VERSION ""

NS_ :

BS_:

BU_: SLU TCU ECU ETAS

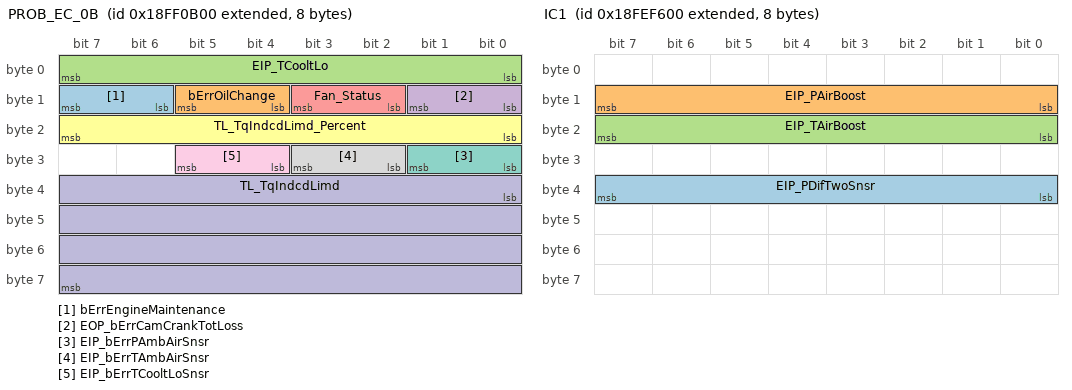
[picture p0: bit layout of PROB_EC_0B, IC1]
BO_ 2566851328 PROB_EC_0B: 8 ECU
 SG_ bErrEngineMaintenance : 14|2@1+ (1,0) [0|1] "" Vector__XXX
 SG_ bErrOilChange : 12|2@1+ (1,0) [0|1] "" Vector__XXX
 SG_ EIP_TCooltLo : 0|8@1+ (1,0) [0|0] "" Vector__XXX
 SG_ EOP_bErrCamCrankTotLoss : 8|2@1+ (1,0) [0|2] "" Vector__XXX
 SG_ Fan_Status : 10|2@1+ (1,0) [0|3] "" Vector__XXX
 SG_ TL_TqIndcdLimd_Percent : 16|8@1+ (1,0) [0|0] "" Vector__XXX
 SG_ EIP_bErrPAmbAirSnsr : 24|2@1+ (1,0) [0|0] "" Vector__XXX
 SG_ EIP_bErrTAmbAirSnsr : 26|2@1+ (1,0) [0|0] "" Vector__XXX
 SG_ EIP_bErrTCooltLoSnsr : 28|2@1+ (1,0) [0|0] "" Vector__XXX
 SG_ TL_TqIndcdLimd : 32|32@1+ (1,0) [0|0] "" Vector__XXX

BO_ 2566842624 LFC: 8 ECU
 SG_ EOP_FuCns : 0|32@1- (0.5,0) [0|2105540607.5] "L" Vector__XXX

BO_ 2566850816 PROB_EC_09: 8 ECU
 SG_ EIP_bErrAccrSnsr1 : 34|2@1+ (1,0) [0|3] ""  TCU
 SG_ EIP_bErrAutStrtSwt : 32|2@1+ (1,0) [0|3] ""  TCU
 SG_ EIP_bErrCmbtSwt : 30|2@1+ (1,0) [0|3] ""  TCU
 SG_ EIP_bErrStpSwt : 28|2@1+ (1,0) [0|3] ""  TCU
 SG_ EIP_StAirFilClgg : 26|2@1+ (1,0) [0|3] ""  TCU
 SG_ WM_bAcvLimp : 24|2@1+ (1,0) [0|3] ""  TCU
 SG_ EIP_bAcvEmgcyShtdwnForOvspd : 22|2@1+ (1,0) [0|3] ""  TCU
 SG_ EIP_bAcvFuCutoffForOvspd : 20|2@1+ (1,0) [0|3] ""  TCU
 SG_ EOP_bAcvCdstFan : 18|2@1+ (1,0) [0|3] ""  TCU
 SG_ EOP_bReqCoolgFanMax : 16|2@1+ (1,0) [0|3] ""  TCU
 SG_ SC_bAcvDDStrtrNotTurn : 14|2@1+ (1,0) [0|3] ""  TCU
 SG_ SC_bAcvDDPinionNotEngd : 12|2@1+ (1,0) [0|3] ""  TCU
 SG_ EIP_bErrGridHeatr : 10|2@1+ (1,0) [0|3] ""  TCU
 SG_ WM_bAcvTCooltHiOvWarn : 8|2@1+ (1,0) [0|3] ""  TCU
 SG_ WM_bAcvLvlOilWarn : 6|2@1+ (1,0) [0|3] ""  TCU
 SG_ WM_bAcvEmgcyShtdwn : 0|2@1+ (1,0) [0|3] ""  TCU
 SG_ WM_bAcvRedn : 4|2@1+ (1,0) [0|3] "" Vector__XXX
 SG_ WM_bAcvWarn : 2|2@1+ (1,0) [0|3] "" Vector__XXX
 SG_ EIP_bErrAccrSnsr2 : 36|2@1+ (1,0) [0|3] "" Vector__XXX
 SG_ EIP_bErrUClmp30Snsr : 38|2@1+ (1,0) [0|3] "" Vector__XXX
 SG_ EIP_bErrAcvUClmp30Snsr : 40|2@1+ (1,0) [0|3] "" Vector__XXX
 SG_ INP_bErrCamsftSnsr : 54|2@1+ (1,0) [0|3] "" Vector__XXX
 SG_ EIP_bErrAcvUClmp48Snsr : 42|2@1+ (1,0) [0|3] "" Vector__XXX
 SG_ EIP_bErrAcvUClmp50 : 44|2@1+ (1,0) [0|3] "" Vector__XXX
 SG_ EIP_bErrAccrRedncy : 46|2@1+ (1,0) [0|3] "" Vector__XXX
 SG_ EOP_bErrAccrTotLoss : 48|2@1+ (1,0) [0|3] "" Vector__XXX
 SG_ WM_bAcvTEcuWarn : 50|2@1+ (1,0) [0|3] "" Vector__XXX
 SG_ INP_bErrCrnksftSnsr : 52|2@1+ (1,0) [0|3] "" Vector__XXX
 SG_ EIP_bErrPFuSnsr : 56|2@1+ (1,0) [0|3] "" Vector__XXX
 SG_ WM_bPRailTooLoMsg : 58|2@1+ (1,0) [0|3] "" Vector__XXX
 SG_ WM_bPRailHiMsg : 60|2@1+ (1,0) [0|3] "" Vector__XXX
 SG_ WM_bPRailTooHiMsg : 62|2@1+ (1,0) [0|3] "" Vector__XXX

BO_ 2566851326 PROB_EC_0A: 8 ECU
 SG_ EIP_bErrLvlOilSnsr : 36|2@1+ (1,0) [0|3] "" Vector__XXX
 SG_ WM_bAcvPOilWarn : 32|2@1+ (1,0) [0|3] "" Vector__XXX
 SG_ EIP_bErrTOilSnsr : 34|2@1+ (1,0) [0|3] "" Vector__XXX
 SG_ EIP_bErrPOilSnsr : 30|2@1+ (1,0) [0|3] ""  TCU
 SG_ WM_bAcvLvlCooltWarn : 28|2@1+ (1,0) [0|3] ""  TCU
 SG_ EIP_bErrLvlCooltSnsr : 26|2@1+ (1,0) [0|3] ""  TCU
 SG_ EIP_bErrTCooltHiSnsr : 24|2@1+ (1,0) [0|3] ""  TCU
 SG_ EIP_bErrInjr8 : 14|2@1+ (1,0) [0|3] ""  TCU
 SG_ EIP_bErrInjr7 : 12|2@1+ (1,0) [0|3] ""  TCU
 SG_ EIP_bErrInjr6 : 10|2@1+ (1,0) [0|3] ""  TCU
 SG_ EIP_bErrInjr5 : 8|2@1+ (1,0) [0|3] ""  TCU
 SG_ EIP_bErrInjr4 : 6|2@1+ (1,0) [0|3] ""  TCU
 SG_ EIP_bErrInjr3 : 4|2@1+ (1,0) [0|3] ""  TCU
 SG_ EIP_bErrInjr2 : 2|2@1+ (1,0) [0|3] ""  TCU
 SG_ EIP_bErrInjr1 : 0|2@1+ (1,0) [0|3] ""  TCU
 SG_ EIP_bAcvSbmgSwt : 38|2@1+ (1,0) [0|3] "" Vector__XXX
 SG_ EOP_bAcvStrtr : 46|2@1+ (1,0) [0|3] "" Vector__XXX
 SG_ EIP_bAcvImdtStrtSwt : 42|2@1+ (1,0) [0|3] "" Vector__XXX
 SG_ EIP_bAcvCmbtSwt : 44|2@1+ (1,0) [0|3] "" Vector__XXX
 SG_ EIP_bAcvCmndrHtchSwt : 40|2@1+ (1,0) [0|3] "" Vector__XXX
 SG_ InjBankAOverCrrnt : 48|2@1+ (2,0) [0|2] "" Vector__XXX
 SG_ InjBankBOverCrrnt : 50|2@1+ (2,0) [0|2] "" Vector__XXX
 SG_ InjBankCOverCrrnt : 52|2@1+ (2,0) [0|2] "" Vector__XXX
 SG_ InjBankDOverCrrnt : 54|2@1+ (2,0) [0|2] "" Vector__XXX
 SG_ GridHeaterReady : 56|2@1+ (1,0) [0|0] "" Vector__XXX

BO_ 2566847488 DD: 8 ECU
 SG_ EIP_LvlFu : 8|8@1+ (0.4,0) [0|100] "%"  TCU

BO_ 2566846208 VEP1: 8 ECU
 SG_ EIP_UClmp30 : 48|16@1+ (0.05,0) [0|3212.75] "V"  TCU

BO_ 2566845952 IC1: 8 ECU
 SG_ EIP_PDifTwoSnsr : 32|8@1+ (0.05,0) [0|12.5] "kPa" Vector__XXX
 SG_ EIP_PAirBoost : 8|8@1+ (2,0) [0|500] "kPa" Vector__XXX
 SG_ EIP_TAirBoost : 16|8@1+ (1,-40) [-40|210] "degC"  TCU

BO_ 2566845696 AMB: 8 ECU
 SG_ EIP_TAmbAir : 24|16@1+ (0.03125,-273) [-273|1735] "deg C"  TCU
 SG_ EIP_PAmbAir : 0|8@1+ (0.5,0) [0|125] "kPa"  TCU

BO_ 2566844928 LFE: 8 ECU
 SG_ IC_InstFuCnsMm3PerHour : 0|16@1+ (0.05,0) [0|3212.75] "L/h"  TCU

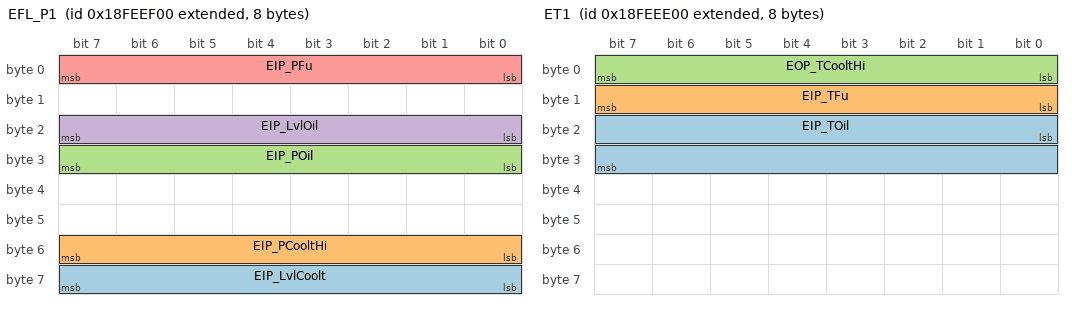
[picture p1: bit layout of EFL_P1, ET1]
BO_ 2566844160 EFL_P1: 8 ECU
 SG_ EIP_LvlCoolt : 56|8@1+ (0.4,0) [0|100] "%"  TCU
 SG_ EIP_PCooltHi : 48|8@1+ (2,0) [0|500] "kPa"  TCU
 SG_ EIP_POil : 24|8@1+ (4,0) [0|1000] "kPa"  TCU
 SG_ EIP_LvlOil : 16|8@1+ (0.4,0) [0|100] "%"  TCU
 SG_ EIP_PFu : 0|8@1+ (4,0) [0|1000] "kPa"  TCU

BO_ 2566843904 ET1: 8 ECU
 SG_ EIP_TOil : 16|16@1+ (0.03125,-273) [-273|1735] "degC"  TCU
 SG_ EIP_TFu : 8|8@1+ (1,-40) [-40|210] "degC"  TCU
 SG_ EOP_TCooltHi : 0|8@1+ (1,-40) [-40|210] "degC"  TCU

BO_ 2566839040 EFL_P2: 8 ECU
 SG_ RPG_PercgFmuVlv2Req : 48|16@1+ (0.00390625,0) [0|251] "Mpa" Vector__XXX
 SG_ EIP_PRail : 16|16@1+ (0.00390625,0) [0|251] "MPa" Vector__XXX

BO_ 2566784768 ET: 8 ECU
 SG_ EIP_TExhLe : 16|16@1+ (0.03125,-273) [-273|1735] "degC"  TCU
 SG_ EIP_TExhRi : 0|16@1+ (0.03125,-273) [-273|1735] "degC"  TCU

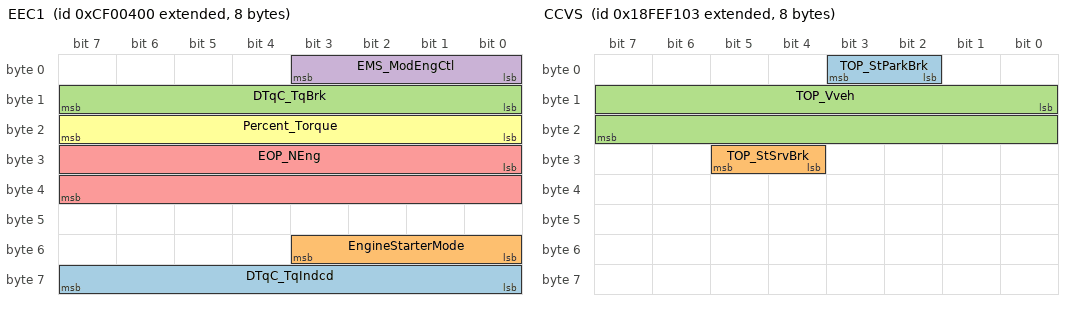
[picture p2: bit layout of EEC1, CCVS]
BO_ 2364539904 EEC1: 8 ECU
 SG_ DTqC_TqIndcd : 56|8@1+ (1,-125) [-125|125] "%" Vector__XXX
 SG_ EngineStarterMode : 48|4@1+ (1,0) [0|15] "" Vector__XXX
 SG_ DTqC_TqBrk : 8|8@1+ (1,-125) [-125|125] "%" Vector__XXX
 SG_ EMS_ModEngCtl : 0|4@1+ (1,0) [0|15] "" Vector__XXX
 SG_ EOP_NEng : 24|16@1+ (0.125,0) [0|8031.875] "rpm"  TCU
 SG_ Percent_Torque : 16|8@1+ (1,-125) [-125|125] "%"  TCU

BO_ 2364539648 EEC2: 3 ECU
 SG_ EIP_PercgAccr2 : 32|8@1+ (0.4,0) [0|100] "%" Vector__XXX
 SG_ DTqC_TqFric : 16|8@1+ (1,0) [0|250] "%" Vector__XXX
 SG_ EIP_PercgAccr1 : 8|8@1+ (0.4,0) [0|100] "%"  TCU

BO_ 2365428224 EOI: 8 ECU
 SG_ EngineOperatingState : 0|4@1+ (1,0) [0|15] "" Vector__XXX

BO_ 2566873347 PROB_TC_061: 8 TCU
 SG_ TOP_NEngReq : 0|32@1+ (1,0) [0|0] "" Vector__XXX

BO_ 2565872899 SAS: 8 TCU
 SG_ TIP_PercgSteer : 0|16@1+ (0.0009765625,-31.374) [-31.374|31.374] "rad" Vector__XXX

BO_ 2566844675 CCVS: 8 TCU
 SG_ TOP_StParkBrk : 2|2@1+ (1,0) [0|3] "" Vector__XXX
 SG_ TOP_StSrvBrk : 28|2@1+ (1,0) [0|3] "" Vector__XXX
 SG_ TOP_Vveh : 8|16@1+ (0.00390625,0) [0|250.996] "km/h" Vector__XXX

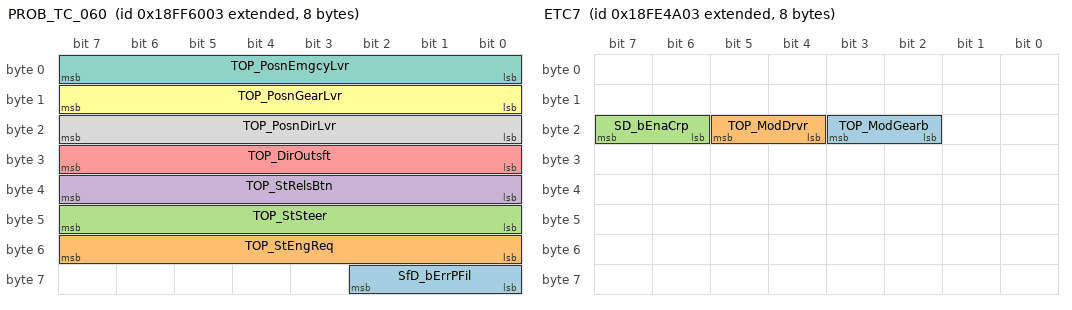
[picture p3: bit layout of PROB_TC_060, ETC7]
BO_ 2566873091 PROB_TC_060: 8 TCU
 SG_ SfD_bErrPFil : 56|3@1+ (1,0) [0|7] "" Vector__XXX
 SG_ TOP_StEngReq : 48|8@1+ (1,0) [0|255] "" Vector__XXX
 SG_ TOP_StSteer : 40|8@1+ (1,0) [0|255] "" Vector__XXX
 SG_ TOP_StRelsBtn : 32|8@1+ (1,0) [0|255] "" Vector__XXX
 SG_ TOP_DirOutsft : 24|8@1+ (1,0) [0|255] "" Vector__XXX
 SG_ TOP_PosnGearLvr : 8|8@1+ (1,0) [0|255] "" Vector__XXX
 SG_ TOP_PosnEmgcyLvr : 0|8@1+ (1,0) [0|255] "" Vector__XXX
 SG_ TOP_PosnDirLvr : 16|8@1+ (1,0) [0|0] "" Vector__XXX

BO_ 2348875779 TC1: 8 TCU
 SG_ SD_bStallLaunAcv : 50|4@1+ (1,0) [0|15] "" Vector__XXX

BO_ 2566801923 ETC7: 8 TCU
 SG_ TOP_ModGearb : 18|2@1+ (1,0) [0|3] "" Vector__XXX
 SG_ TOP_ModDrvr : 20|2@1+ (1,0) [0|3] "" Vector__XXX
 SG_ SD_bEnaCrp : 22|2@1+ (1,0) [0|3] "" Vector__XXX

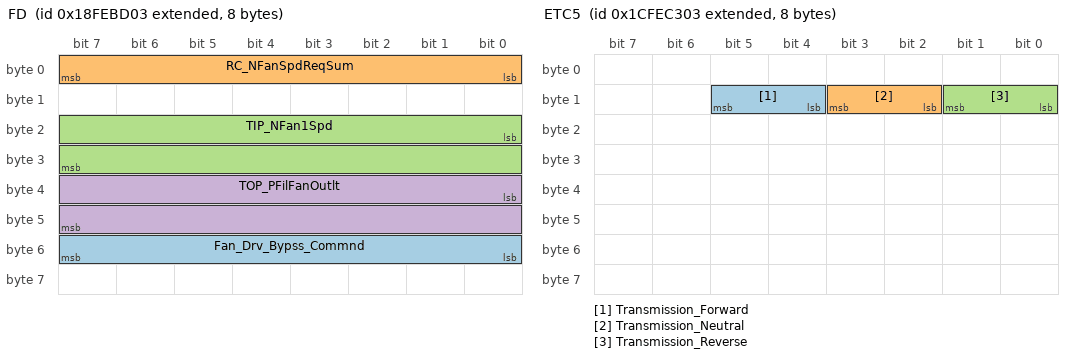
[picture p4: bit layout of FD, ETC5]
BO_ 2566831363 FD: 8 TCU
 SG_ Fan_Drv_Bypss_Commnd : 48|8@1+ (0.4,0) [0|100] "%" Vector__XXX
 SG_ RC_NFanSpdReqSum : 0|8@1+ (0.4,0) [0|100] "%" Vector__XXX
 SG_ TIP_NFan1Spd : 16|16@1+ (0.125,0) [0|8031.875] "rpm" Vector__XXX
 SG_ TOP_PFilFanOutlt : 32|16@1+ (0.5,0) [0|32127.5] "kPa" Vector__XXX

BO_ 2365449731 HBS: 8 TCU
 SG_ SfD_bErrPAcmtrSrvBrkLo : 26|2@1+ (1,0) [0|3] "" Vector__XXX

BO_ 2633941763 ETC5: 8 TCU
 SG_ Transmission_Forward : 12|2@1+ (1,0) [0|3] "" Vector__XXX
 SG_ Transmission_Neutral : 10|2@1+ (1,0) [0|3] "" Vector__XXX
 SG_ Transmission_Reverse : 8|2@1+ (1,0) [0|3] "" Vector__XXX

BO_ 2566846467 TRF1: 8 TCU
 SG_ TIP_TTqcInlt : 32|16@1+ (0.03125,-273) [-273|1735] "deg C" Vector__XXX

BO_ 2565866755 ETC2: 8 TCU
 SG_ GS_IdxGearDes : 0|8@1+ (1,-125) [-125|125] "" Vector__XXX
 SG_ TOP_Trans_ActlGearRtio : 8|16@1+ (0.001,0) [0|64.255] "" Vector__XXX
 SG_ TOP_IdxGearAcv : 24|8@1+ (1,-125) [-125|125] "" Vector__XXX
 SG_ Trans_Reqstd_Rng : 40|16@1+ (1,0) [0|255] "" Vector__XXX
 SG_ Trans_Current_Rng : 48|16@1+ (1,0) [0|255] "" Vector__XXX

BO_ 2364539395 ETC1: 8 TCU
 SG_ TIP_NOutsft : 8|16@1+ (0.125,0) [0|8031.875] "rpm" Vector__XXX

BO_ 2566873603 PROB_TC_062: 8 TCU
 SG_ TIP_PSrvBrk : 0|2@1+ (1,0) [0|0] "" Vector__XXX
 SG_ TIP_bErrFanSoln : 22|2@1+ (1,0) [0|0] "" Vector__XXX
 SG_ SfD_bErrPTqcInltLo : 30|2@1+ (1,0) [0|0] "" Vector__XXX
 SG_ TOP_bErrTqcOutltP : 32|2@1+ (1,0) [0|0] "" Vector__XXX
 SG_ TOP_bErrTqcInltT : 34|2@1+ (1,0) [0|0] "" Vector__XXX
 SG_ TOP_bErrTqcOutltT : 36|2@1+ (1,0) [0|0] "" Vector__XXX
 SG_ SD_bEnaDirLock : 38|2@1+ (1,0) [0|0] "" Vector__XXX
 SG_ TOP_Brake_Pstn_Oil_Prssure : 40|2@1+ (1,0) [0|0] "" Vector__XXX
 SG_ EIP_bAcvEmgcyShtdwn : 42|2@1+ (1,0) [0|0] "" Vector__XXX
 SG_ SfD_bErrSrvBrkRiWear : 2|2@1+ (1,0) [0|0] "" Vector__XXX
 SG_ SfD_bErrSrvBrkLeWear : 4|2@1+ (1,0) [0|0] "" Vector__XXX
 SG_ TIP_StParkBrk : 6|2@1+ (1,0) [0|0] "" Vector__XXX
 SG_ TIP_bErrFanOilT : 8|2@1+ (1,0) [0|0] "" Vector__XXX
 SG_ TIP_bErrFanOilP : 10|2@1+ (1,0) [0|0] "" Vector__XXX
 SG_ TIP_bErrFanOilLimSwtLvl : 12|2@1+ (1,0) [0|0] "" Vector__XXX
 SG_ SfD_bErrPFilFanClgg : 14|2@1+ (1,0) [0|0] "" Vector__XXX
 SG_ SfD_bErrTOilHi : 16|2@1+ (1,0) [0|0] "" Vector__XXX
 SG_ SfD_bErrSrvBrkRiLeWear : 18|2@1+ (1,0) [0|0] "" Vector__XXX
 SG_ SfD_bErrTOilLo : 20|2@1+ (1,0) [0|0] "" Vector__XXX
 SG_ SfD_bErrPHydSteerUniLo : 24|2@1+ (1,0) [0|0] "" Vector__XXX
 SG_ SfD_bErrPFilAnclryOutltLo : 26|2@1+ (1,0) [0|0] "" Vector__XXX
 SG_ SfD_bErrPLubOutltLo : 28|2@1+ (1,0) [0|0] "" Vector__XXX
 SG_ TOP_bErrTrvlDir : 46|2@1+ (1,0) [0|0] "" Vector__XXX
 SG_ TIP_bErrOutsftN : 44|2@1+ (1,0) [0|0] "" Vector__XXX
 SG_ TOP_bErrTqcInltP : 50|2@1+ (1,0) [0|0] "" Vector__XXX
 SG_ TOP_bErrSrvBrkAcmtrP : 48|2@1+ (1,0) [0|0] "" Vector__XXX
 SG_ SD_LvlHill : 56|8@1+ (1,-125) [-125|125] "" Vector__XXX

BO_ 2566877193 PROB_ETAS_1: 8 ETAS
 SG_ ETAS_RS_PerSec : 0|32@1+ (1,0) [0|10000] "" Vector__XXX

BO_ 2566877449 PROB_ETAS_2: 8 ETAS
 SG_ ETAS_Torque : 0|32@1+ (1,0) [0|10000] "" Vector__XXX

CM_ BU_ SLU "Shift Lever Unit";
CM_ BU_ TCU "Transmission Control Unit";
CM_ BU_ ECU "Engine Control Unit";
CM_ BU_ ETAS "ETAS";
CM_ BO_ 2566851328 "PROB_EC_0B Engine Control";
CM_ SG_ 2566851328 bErrEngineMaintenance "Alternator";
CM_ SG_ 2566851328 bErrOilChange "Alternator";
CM_ SG_ 2566851328 Fan_Status "Fan Status";
CM_ SG_ 2566851328 TL_TqIndcdLimd_Percent "%";
CM_ BO_ 2566842624 " Fuel Consumption (Liquid) - LFC";
CM_ SG_ 2566842624 EOP_FuCns "Engine Trip Fuel";
CM_ BO_ 2566850816 "PROB_EC_09 Engine Control";
CM_ BO_ 2566851326 "PROB_EC_0A Engine Control";
CM_ SG_ 2566851326 EIP_bErrTOilSnsr "
";
CM_ SG_ 2566851326 GridHeaterReady "PHC_bAcvPreAcvnGridHeatr=0 oldu?unda motor ön ?s?tma sistemi bak?m?ndan çal??t?r?lmaya haz?rd?r.";
CM_ BO_ 2566847488 "Dash Display";
CM_ SG_ 2566847488 EIP_LvlFu "Fuel Level 1";
CM_ BO_ 2566846208 "Vehicle Electrical Power 1";
CM_ SG_ 2566846208 EIP_UClmp30 "Keyswitch Battery Potential";
CM_ BO_ 2566845952 "Inlet/Exaust Conditions 1";
CM_ SG_ 2566845952 EIP_PDifTwoSnsr "Engine Air Filter 1 Differential Pressure";
CM_ SG_ 2566845952 EIP_PAirBoost "Engine Intake Manifold #1 Pressure";
CM_ SG_ 2566845952 EIP_TAirBoost "Engine Intake Manifold 1 Temperature";
CM_ BO_ 2566845696 "Ambient Conditions";
CM_ SG_ 2566845696 EIP_TAmbAir "Ambient Air Temperature";
CM_ SG_ 2566845696 EIP_PAmbAir "Ambient Air Pressure";
CM_ BO_ 2566844928 "Fuel Economy (Liquid)";
CM_ SG_ 2566844928 IC_InstFuCnsMm3PerHour "Engine Fuel Rate";
CM_ BO_ 2566844160 "Engine Fluid Level Pressure 1";
CM_ SG_ 2566844160 EIP_LvlCoolt "Engine Coolant Level";
CM_ SG_ 2566844160 EIP_PCooltHi "Engine Coolant Pressure";
CM_ SG_ 2566844160 EIP_POil "Engine Oil Pressure";
CM_ SG_ 2566844160 EIP_LvlOil "Engine Oil Level";
CM_ SG_ 2566844160 EIP_PFu "Engine Fuel Delivery Pressure";
CM_ BO_ 2566843904 "Engine Temperature 1";
CM_ SG_ 2566843904 EIP_TOil "Engine Oil Temperature 1";
CM_ SG_ 2566843904 EIP_TFu "Engine Fuel Temperature 1";
CM_ SG_ 2566843904 EOP_TCooltHi "Engine Coolant Temperature";
CM_ BO_ 2566839040 "Engine Fluid Level Pressure 2";
CM_ SG_ 2566839040 RPG_PercgFmuVlv2Req "Engine Injector Metering Rail 2 Pressure";
CM_ SG_ 2566839040 EIP_PRail "Engine Injection Control Pressure";
CM_ BO_ 2566784768 "Exhaust Temperature";
CM_ SG_ 2566784768 EIP_TExhLe "Engine Exhaust Gas Temperature - Left Manifold";
CM_ SG_ 2566784768 EIP_TExhRi "Engine Exhaust Gas Temperature - Right Manifold";
CM_ BO_ 2364539904 "Electronic Engine Controller 1";
CM_ SG_ 2364539904 DTqC_TqIndcd "Engine Demand – Percent Torque";
CM_ SG_ 2364539904 EngineStarterMode "Engine Starter Mode";
CM_ SG_ 2364539904 DTqC_TqBrk "Driver's Demand Engine - Percent Torque";
CM_ SG_ 2364539904 EMS_ModEngCtl "Engine Torque Mode";
CM_ SG_ 2364539904 EOP_NEng "Engine Speed";
CM_ SG_ 2364539904 Percent_Torque "Actual Engine - Percent Torque";
CM_ BO_ 2364539648 "Electronic Engine Controller 2";
CM_ SG_ 2364539648 EIP_PercgAccr2 "Accelerator Pedal Position 2";
CM_ SG_ 2364539648 DTqC_TqFric "Engine Percent Load At Current Speed";
CM_ SG_ 2364539648 EIP_PercgAccr1 "Accelerator Pedal Position 1";
CM_ BO_ 2365428224 "Engine Operating Information";
CM_ SG_ 2365428224 EngineOperatingState "Engine Operating State";
CM_ BO_ 2566873347 "PROB_TC_061 Transmission Control";
CM_ BO_ 2565872899 "Steering Angle Sensor Information";
CM_ SG_ 2565872899 TIP_PercgSteer "Steering Wheel Angle";
CM_ BO_ 2566844675 "Cruise Control/Vehicle Speeds";
CM_ SG_ 2566844675 TOP_StParkBrk "Parking Brake Switch";
CM_ SG_ 2566844675 TOP_StSrvBrk "Brake Switch";
CM_ SG_ 2566844675 TOP_Vveh "Wheel-Based Vehicle Speed";
CM_ BO_ 2566873091 "PROB_TC_060 Transmission Control";
CM_ BO_ 2348875779 "Transmission Control 1";
CM_ SG_ 2348875779 SD_bStallLaunAcv "Transmission Requested Launch Gear";
CM_ BO_ 2566801923 "Electronic Transmission Controller 7";
CM_ SG_ 2566801923 TOP_ModGearb "Transmission Mode 3 Indicator";
CM_ SG_ 2566801923 TOP_ModDrvr "Transmission Mode 2 Indicator";
CM_ SG_ 2566801923 SD_bEnaCrp "Transmission Mode 1 Indicator";
CM_ BO_ 2566831363 "Fan Drive";
CM_ SG_ 2566831363 Fan_Drv_Bypss_Commnd "Fan Drive Bypass Command Status";
CM_ SG_ 2566831363 RC_NFanSpdReqSum "Estimated Percent Fan Speed";
CM_ SG_ 2566831363 TIP_NFan1Spd "Fan Speed";
CM_ SG_ 2566831363 TOP_PFilFanOutlt "Hydraulic Fan Motor Pressure";
CM_ BO_ 2365449731 "Hydraulic Braking System";
CM_ SG_ 2365449731 SfD_bErrPAcmtrSrvBrkLo "Hydraulic Brake Fluid Level Switch";
CM_ BO_ 2633941763 "Electronic Transmission Controller 5";
CM_ SG_ 2633941763 Transmission_Forward "Transmission Forward Direction Switch";
CM_ SG_ 2633941763 Transmission_Neutral "Transmission Neutral Switch";
CM_ SG_ 2633941763 Transmission_Reverse "Transmission Reverse Direction Switch";
CM_ BO_ 2566846467 "Transmission Fluids 1";
CM_ SG_ 2566846467 TIP_TTqcInlt "Transmission Oil Temperature";
CM_ BO_ 2565866755 "Electronic Transmission Controller 2";
CM_ SG_ 2565866755 GS_IdxGearDes "Transmission Selected Gear";
CM_ SG_ 2565866755 TOP_Trans_ActlGearRtio "Transmission Actual Gear Ratio";
CM_ SG_ 2565866755 TOP_IdxGearAcv "Transmission Current Gear";
CM_ SG_ 2565866755 Trans_Reqstd_Rng "Transmission Requested Range";
CM_ SG_ 2565866755 Trans_Current_Rng "Transmission Current Range";
CM_ BO_ 2364539395 "Electronic Transmission Controller 1";
CM_ SG_ 2364539395 TIP_NOutsft "Transmission Output Shaft Speed";
CM_ BO_ 2566873603 "PROB_TC_062 Transmission Control";
CM_ BO_ 2566877193 "ETAS1";
CM_ BO_ 2566877449 "ETAS2";
BA_DEF_ SG_  "SigType" ENUM  "Default","Range","RangeSigned","ASCII","Discrete","Control","ReferencePGN","DTC","StringDelimiter","StringLength","StringLengthControl","MessageCounter","MessageChecksum";
BA_DEF_ SG_  "GenSigEVName" STRING ;
BA_DEF_ SG_  "GenSigILSupport" ENUM  "No","Yes";
BA_DEF_ SG_  "GenSigSendType" ENUM  "Cyclic","OnWrite","OnWriteWithRepetition","OnChange","OnChangeWithRepetition","IfActive","IfActiveWithRepetition","NoSigSendType";
BA_DEF_ SG_  "GenSigStartValue" INT 0 2147483647;
BA_DEF_ BO_  "GenMsgILSupport" ENUM  "No","Yes";
BA_DEF_ BU_  "NmStationAddress" INT 0 255;
BA_DEF_ BO_  "GenMsgSendType" ENUM  "cyclic","NotUsed","IfActive","NotUsed","NotUsed","NotUsed","NotUsed","NotUsed","noMsgSendType";
BA_DEF_ BO_  "GenMsgRequestable" INT 0 1;
BA_DEF_ BO_  "GenMsgCycleTime" INT 0 3600000;
BA_DEF_  "DBName" STRING ;
BA_DEF_  "BusType" STRING ;
BA_DEF_  "ProtocolType" STRING ;
BA_DEF_ BO_  "VFrameFormat" ENUM  "StandardCAN","ExtendedCAN","reserved","J1939PG";
BA_DEF_DEF_  "SigType" "Default";
BA_DEF_DEF_  "GenSigEVName" "Env@Nodename_@Signame";
BA_DEF_DEF_  "GenSigILSupport" "Yes";
BA_DEF_DEF_  "GenSigSendType" "NoSigSendType";
BA_DEF_DEF_  "GenSigStartValue" 0;
BA_DEF_DEF_  "GenMsgILSupport" "Yes";
BA_DEF_DEF_  "NmStationAddress" 254;
BA_DEF_DEF_  "GenMsgSendType" "noMsgSendType";
BA_DEF_DEF_  "GenMsgRequestable" 1;
BA_DEF_DEF_  "GenMsgCycleTime" 0;
BA_DEF_DEF_  "DBName" "";
BA_DEF_DEF_  "BusType" "CAN";
BA_DEF_DEF_  "ProtocolType" "J1939";
BA_DEF_DEF_  "VFrameFormat" "J1939PG";
BA_ "DBName" "canidentifiers";
BA_ "GenMsgCycleTime" BO_ 2566851328 10000;
BA_ "GenMsgSendType" BO_ 2566850816 0;
BA_ "GenMsgCycleTime" BO_ 2566850816 50;
BA_ "GenMsgSendType" BO_ 2566851326 0;
BA_ "GenMsgCycleTime" BO_ 2566851326 50;
BA_ "GenMsgSendType" BO_ 2566847488 0;
BA_ "GenMsgCycleTime" BO_ 2566847488 1000;
BA_ "GenMsgSendType" BO_ 2566846208 0;
BA_ "GenMsgCycleTime" BO_ 2566846208 1000;
BA_ "GenMsgSendType" BO_ 2566845952 0;
BA_ "GenMsgCycleTime" BO_ 2566845952 500;
BA_ "GenSigStartValue" SG_ 2566845952 EIP_TAirBoost 40;
BA_ "GenMsgSendType" BO_ 2566845696 0;
BA_ "GenMsgCycleTime" BO_ 2566845696 1000;
BA_ "GenSigStartValue" SG_ 2566845696 EIP_TAmbAir 8736;
BA_ "GenMsgSendType" BO_ 2566844928 0;
BA_ "GenMsgCycleTime" BO_ 2566844928 100;
BA_ "GenMsgSendType" BO_ 2566844160 0;
BA_ "GenMsgCycleTime" BO_ 2566844160 1000;
BA_ "GenMsgSendType" BO_ 2566843904 0;
BA_ "GenMsgCycleTime" BO_ 2566843904 1000;
BA_ "GenSigStartValue" SG_ 2566843904 EIP_TOil 8736;
BA_ "GenSigStartValue" SG_ 2566843904 EIP_TFu 40;
BA_ "GenSigStartValue" SG_ 2566843904 EOP_TCooltHi 40;
BA_ "GenMsgCycleTime" BO_ 2566839040 500;
BA_ "GenMsgSendType" BO_ 2566839040 0;
BA_ "GenMsgCycleTime" BO_ 2566784768 500;
BA_ "GenMsgSendType" BO_ 2566784768 0;
BA_ "GenSigStartValue" SG_ 2566784768 EIP_TExhLe 8736;
BA_ "GenSigStartValue" SG_ 2566784768 EIP_TExhRi 8736;
BA_ "GenMsgCycleTime" BO_ 2364539904 10;
BA_ "GenMsgSendType" BO_ 2364539904 0;
BA_ "GenSigStartValue" SG_ 2364539904 DTqC_TqIndcd 125;
BA_ "GenSigStartValue" SG_ 2364539904 DTqC_TqBrk 125;
BA_ "GenSigStartValue" SG_ 2364539904 Percent_Torque 125;
BA_ "GenMsgCycleTime" BO_ 2364539648 50;
BA_ "GenMsgSendType" BO_ 2364539648 0;
BA_ "NmStationAddress" BU_ SLU 5;
BA_ "NmStationAddress" BU_ TCU 3;
BA_ "NmStationAddress" BU_ ECU 0;
BA_ "NmStationAddress" BU_ ETAS 9;
VAL_ 2566851328 bErrEngineMaintenance 1 "Error" 0 "No Error" ;
VAL_ 2566851328 bErrOilChange 1 "Error" 0 "No Error" ;
VAL_ 2566851328 EOP_bErrCamCrankTotLoss 0 "NO ERROR" 1 "ERROR" ;
VAL_ 2566851328 Fan_Status 0 "FAN CLOSE" 1 "FAN MAX" 2 "DEFAULT" 3 "ERROR" ;
VAL_ 2566850816 EIP_bErrAccrSnsr1 3 "Error" 2 "N/A" 1 "On" 0 "Off" ;
VAL_ 2566850816 EIP_bErrAutStrtSwt 3 "Error" 2 "N/A" 1 "On" 0 "Off" ;
VAL_ 2566850816 EIP_bErrCmbtSwt 3 "Error" 2 "N/A" 1 "On" 0 "Off" ;
VAL_ 2566850816 EIP_bErrStpSwt 3 "Error" 2 "N/A" 1 "On" 0 "Off" ;
VAL_ 2566850816 EIP_StAirFilClgg 3 "Error" 2 "N/A" 1 "On" 0 "Off" ;
VAL_ 2566850816 WM_bAcvLimp 3 "Error" 2 "N/A" 1 "On" 0 "Off" ;
VAL_ 2566850816 EIP_bAcvEmgcyShtdwnForOvspd 3 "Error" 2 "N/A" 1 "On" 0 "Off" ;
VAL_ 2566850816 EIP_bAcvFuCutoffForOvspd 3 "Error" 2 "N/A" 1 "On" 0 "Off" ;
VAL_ 2566850816 EOP_bAcvCdstFan 3 "Error" 2 "N/A" 1 "On" 0 "Off" ;
VAL_ 2566850816 EOP_bReqCoolgFanMax 3 "Error" 2 "N/A" 1 "On" 0 "Off" ;
VAL_ 2566850816 SC_bAcvDDStrtrNotTurn 3 "Error" 2 "N/A" 1 "On" 0 "Off" ;
VAL_ 2566850816 SC_bAcvDDPinionNotEngd 3 "Error" 2 "N/A" 1 "On" 0 "Off" ;
VAL_ 2566850816 EIP_bErrGridHeatr 3 "Error" 2 "N/A" 1 "On" 0 "Off" ;
VAL_ 2566850816 WM_bAcvTCooltHiOvWarn 3 "Error" 2 "N/A" 1 "On" 0 "Off" ;
VAL_ 2566850816 WM_bAcvLvlOilWarn 3 "Error" 2 "N/A" 1 "On" 0 "Off" ;
VAL_ 2566850816 WM_bAcvEmgcyShtdwn 0 "OFF" 1 "ON" 2 "N/A" 3 "ERROR" ;
VAL_ 2566850816 WM_bAcvRedn 0 "OFF" 1 "ON" 2 "N/A" 3 "ERROR" ;
VAL_ 2566850816 WM_bAcvWarn 0 "OFF" 1 "ON" 2 "N/A" 3 "ERROR" ;
VAL_ 2566850816 EIP_bErrAccrSnsr2 0 "OFF" 1 "ON" 2 "N/A" 3 "ERROR" ;
VAL_ 2566850816 EIP_bErrUClmp30Snsr 0 "OFF" 1 "ON" 2 "N/A" 3 "ERROR" ;
VAL_ 2566850816 EIP_bErrAcvUClmp30Snsr 0 "OFF" 1 "ON" 2 "N/A" 3 "ERROR" ;
VAL_ 2566850816 INP_bErrCamsftSnsr 0 "OFF" 3 "ERROR" 2 "N/A" 1 "ON" ;
VAL_ 2566850816 EIP_bErrAcvUClmp48Snsr 0 "OFF" 1 "ON" 2 "N/A" 3 "ERROR" ;
VAL_ 2566850816 EIP_bErrAcvUClmp50 0 "OFF" 1 "ON" 2 "N/A" 3 "ERROR" ;
VAL_ 2566850816 EIP_bErrAccrRedncy 0 "OFF" 1 "ON" 2 "N/A" 3 "ERROR" ;
VAL_ 2566850816 EOP_bErrAccrTotLoss 0 "OFF" 1 "ON" 2 "N/A" 3 "ERROR" ;
VAL_ 2566850816 WM_bAcvTEcuWarn 0 "OFF" 1 "ON" 2 "N/A" 3 "ERROR" ;
VAL_ 2566850816 INP_bErrCrnksftSnsr 0 "OFF" 1 "ON" 2 "N/A" 3 "ERROR" ;
VAL_ 2566851326 EIP_bErrLvlOilSnsr 0 "OFF" 1 "ON" 2 "N/A" 3 "ERROR" ;
VAL_ 2566851326 WM_bAcvPOilWarn 3 "Error" 2 "N/A" 1 "On" 0 "Off" ;
VAL_ 2566851326 EIP_bErrTOilSnsr 3 "Error" 2 "N/A" 1 "On" 0 "Off" ;
VAL_ 2566851326 EIP_bErrPOilSnsr 3 "Error" 2 "N/A" 1 "On" 0 "Off" ;
VAL_ 2566851326 WM_bAcvLvlCooltWarn 3 "Error" 2 "N/A" 1 "On" 0 "Off" ;
VAL_ 2566851326 EIP_bErrLvlCooltSnsr 3 "Error" 2 "N/A" 1 "On" 0 "Off" ;
VAL_ 2566851326 EIP_bErrTCooltHiSnsr 3 "Error" 2 "N/A" 1 "On" 0 "Off" ;
VAL_ 2566851326 EIP_bErrInjr8 3 "Error" 2 "N/A" 1 "On" 0 "Off" ;
VAL_ 2566851326 EIP_bErrInjr7 3 "Error" 2 "N/A" 1 "On" 0 "Off" ;
VAL_ 2566851326 EIP_bErrInjr6 3 "Error" 2 "N/A" 1 "On" 0 "Off" ;
VAL_ 2566851326 EIP_bErrInjr5 3 "Error" 2 "N/A" 1 "On" 0 "Off" ;
VAL_ 2566851326 EIP_bErrInjr4 3 "Error" 2 "N/A" 1 "On" 0 "Off" ;
VAL_ 2566851326 EIP_bErrInjr3 3 "Error" 2 "N/A" 1 "On" 0 "Off" ;
VAL_ 2566851326 EIP_bErrInjr2 3 "Error" 2 "N/A" 1 "On" 0 "Off" ;
VAL_ 2566851326 EIP_bErrInjr1 3 "Error" 2 "N/A" 1 "On" 0 "Off" ;
VAL_ 2566851326 EIP_bAcvSbmgSwt 0 "OFF" 1 "ON" 2 "N/A" 3 "ERROR" ;
VAL_ 2566851326 EOP_bAcvStrtr 0 "OFF" 1 "ON" 2 "N/A" 3 "ERROR" ;
VAL_ 2566851326 EIP_bAcvImdtStrtSwt 0 "OFF" 1 "ON" 2 "N/A" 3 "ERROR" ;
VAL_ 2566851326 EIP_bAcvCmbtSwt 0 "OFF" 1 "ON" 2 "N/A" 3 "ERROR" ;
VAL_ 2566851326 EIP_bAcvCmndrHtchSwt 0 "OFF" 1 "ON" 2 "N/A" 3 "ERROR" ;
VAL_ 2566851326 InjBankAOverCrrnt 0 "NO ERROR" 1 "ERROR" ;
VAL_ 2566851326 InjBankBOverCrrnt 0 "NO ERROR" 1 "ERROR" ;
VAL_ 2566851326 InjBankCOverCrrnt 0 "NO ERROR" 1 "ERROR" ;
VAL_ 2566851326 InjBankDOverCrrnt 0 "NO ERROR" 1 "ERROR" ;
VAL_ 2364539904 EngineStarterMode 0 "start not requested" 1 "starter active, gear not engaged" 2 "starter active, gear engaged" 3 "start finished; starter not active after having been actively engaged (after 50ms mode goes to 0000)" 4 " starter inhibited due to engine already running" 5 "starter inhibited due to engine not ready for start (preheating)" 6 "starter inhibited due to driveline engaged or other transmission inhibit" 7 "N/A" 8 "starter inhibited due to starter over-temp" 9 "N/A" 10 "N/A" 11 "N/A" 12 "N/A" 13 "N/A" 14 "N/A" 15 "N/A" ;
VAL_ 2364539904 EMS_ModEngCtl 0 "Low idle governor/no request (default mode)" 1 "Accelerator pedal/operator selection" 2 "Cruise control" 3 "PTO governor" 4 "Road speed governor" 5 "ASR control" 6 "Transmission control" 7 "ABS control" 8 "Torque limiting" 9 "High speed governor" 10 "Braking system" 11 "Remote accelerator" 12 "Service procedure" 13 "not defined" 14 "Other" 15 "Not available" ;
VAL_ 2365428224 EngineOperatingState 2 "Starting" 6 "Engine Stopping" ;
VAL_ 2566844675 TOP_StParkBrk 0 "Parking brake not set" 1 "Parking brake set" 2 "ERROR" 3 "N/A" ;
VAL_ 2566844675 TOP_StSrvBrk 0 "Brake pedal released" 1 "Brake pedal depressed" 2 "ERROR" 3 "N/A" ;
VAL_ 2566873091 SfD_bErrPFil 0 "bErrPFilFanClgg-bErrPFilLubClgg-bErrPFilAnclryClgg->OFF" 1 "bErrPFilAnclryClgg->ON" 2 "bErrPFilLubClgg->ON" 3 "bErrPFilLubClgg-bErrPFilAnclryClgg->ON" 4 "bErrPFilFanClgg->ON" 5 "bErrPFilFanClgg-bErrPFilAnclryClgg->ON" 6 "bErrPFilFanClgg-bErrPFilLubClgg->ON" 7 "bErrPFilFanClgg-bErrPFilLubClgg-bErrPFilAnclryClgg->ON" ;
VAL_ 2348875779 SD_bStallLaunAcv 0 "No specific launch gear requested; use default launch gear" 1 "Launch the vehicle in 1st gear" 2 "Launch the vehicle in 2nd gear" 3 "Launch the vehicle in 3nd gear" 4 "Launch the vehicle in 4th gear" 5 "Launch the vehicle in 5th gear" 6 "Launch the vehicle in 6th gear" 7 "Launch the vehicle in 7th gear" 8 "Launch the vehicle in 8th gear" 9 "Launch the vehicle in Reverse 1" 10 "Launch the vehicle in Reverse 2" 11 "Launch the vehicle in Reverse 3" 12 "Launch the vehicle in Reverse 4" 13 "Reserved" 14 "ERROR" 15 "N/A" ;
VAL_ 2566801923 TOP_ModGearb 0 "Disable" 1 "Mod3 Enable" 2 "Reserved" 3 "Take no action" ;
VAL_ 2566801923 TOP_ModDrvr 0 "Disable" 1 "Mod2 Enable" 2 "Reserved" 3 "Take no action" ;
VAL_ 2566801923 SD_bEnaCrp 0 "Disable" 1 "Mod1 Enable" 2 "Reserved" 3 "Take no action" ;
VAL_ 2365449731 SfD_bErrPAcmtrSrvBrkLo 0 "Fluid level is not sufficient" 1 "Fluid level is sufficient" 2 "ERROR" 3 "N/A" ;
VAL_ 2633941763 Transmission_Forward 0 "OFF" 1 "ON" 2 "ERROR" 3 "N/A" ;
VAL_ 2633941763 Transmission_Neutral 0 "OFF" 1 "ON" 2 "ERROR" 3 "N/A" ;
VAL_ 2633941763 Transmission_Reverse 0 "OFF" 1 "ON" 2 "ERROR" 3 "N/A" ;
